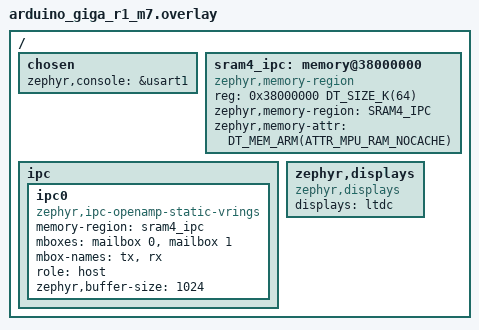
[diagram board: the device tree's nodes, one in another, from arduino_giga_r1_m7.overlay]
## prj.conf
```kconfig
# Gigaspark OS - M7 (Primary Core) Configuration
CONFIG_PRINTK=y
CONFIG_LOG=y
CONFIG_HEAP_MEM_POOL_SIZE=8192
CONFIG_MAIN_STACK_SIZE=4096

# IPC Service
CONFIG_IPC_SERVICE=y
CONFIG_OPENAMP=y
CONFIG_OPENAMP_SLAVE=n

# MBOX driver for STM32 HSEM
CONFIG_MBOX=y

# GPIO for LED
CONFIG_GPIO=y
```

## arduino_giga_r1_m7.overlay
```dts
/*
 * Gigaspark OS - M7 Device Tree Overlay
 * Arduino Giga R1 (STM32H747XI M7)
 *
 * IPC via OpenAMP static vrings over SRAM4
 * LVGL display configuration
 */

#include <zephyr/dt-bindings/ipc_service/static_vrings.h>
#include <zephyr/dt-bindings/memory-attr/memory-attr-arm.h>

/ {
	chosen {
		zephyr,console = &usart1;
	};

	/* SRAM4: 64KB at 0x38000000 (D3 domain, shared between M7 and M4) */
	sram4_ipc: memory@38000000 {
		compatible = "zephyr,memory-region", "mmio-sram";
		reg = <0x38000000 DT_SIZE_K(64)>;
		zephyr,memory-region = "SRAM4_IPC";
		zephyr,memory-attr = <DT_MEM_ARM(ATTR_MPU_RAM_NOCACHE)>;
	};

	/* IPC node for OpenAMP static vrings */
	ipc {
		ipc0: ipc0 {
			compatible = "zephyr,ipc-openamp-static-vrings";
			memory-region = <&sram4_ipc>;
			mboxes = <&mailbox 0>, <&mailbox 1>;
			mbox-names = "tx", "rx";
			role = "host";
			zephyr,buffer-size = <1024>;
			status = "okay";
		};
	};

	/* LVGL display configuration - references the LTDC */
	zephyr,displays {
		compatible = "zephyr,displays";
		displays = <&ltdc>;
	};
};
```

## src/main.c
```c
/*
 * Gigaspark OS - M7 Primary Core
 * STM32H747XI Cortex-M7 @ 480MHz
 *
 * Architecture: 2 Dedicated Threads (Strict Multiplexation)
 *
 * Thread 1 - ui_launcher (Priority: Low):
 *   EXCLUSIVELY handles LVGL rendering, touch input, and the app menu.
 *   Runs lv_timer_handler() in a tight loop at 5ms intervals.
 *   Manages the navigation bar (Home button).
 *
 * Thread 2 - app_runner (Priority: High):
 *   EXCLUSIVELY executes user apps (app_main()) and handles the SDK.
 *   Communicates with M4 via IPC for memory and filesystem ops.
 *   Can be aborted by ui_launcher when Home is pressed.
 *
 * Communication: main() initializes everything, then threads take over.
 */

#include <zephyr/kernel.h>
#include <zephyr/device.h>
#include <zephyr/drivers/gpio.h>
#include <zephyr/ipc/ipc_service.h>
#include <zephyr/logging/log.h>

#include "ipc_config.h"
#include "ipc_protocol.h"
#include "fault_manager.h"
#include "app_runner.h"
#include "nav_bar.h"
#include "power_manager.h"
#include "net_manager.h"
#include "app_downloader.h"

LOG_MODULE_REGISTER(gigaspark_m7, CONFIG_LOG_DEFAULT_LEVEL);

/* SDK init */
extern void gigaspark_sdk_init(void);

/* Green LED = PJ13 (alias led1) */
static const struct gpio_dt_spec led_green = GPIO_DT_SPEC_GET(DT_ALIAS(led1), gpios);

/* ============================================================
 * IPC Layer (shared by both threads)
 * ============================================================ */

static struct ipc_ept ept;
static volatile bool ept_ready;
static K_SEM_DEFINE(bound_sem, 0, 1);
static K_SEM_DEFINE(data_sem, 0, 1);

/* Last response from M4 */
static struct ipc_msg last_resp;

/* Shared buffer for file writes */
uint8_t g_file_write_buf[FILE_WRITE_CHUNK_MAX];

static void ept_bound(void *priv)
{
	(void)priv;
	ept_ready = true;
	k_sem_give(&bound_sem);
	LOG_INF("Endpoint bound to M4");
}

static void ept_received(const void *data, size_t len, void *priv)
{
	(void)priv;
	if (len < sizeof(struct ipc_msg)) {
		return;
	}

	memcpy(&last_resp, data, sizeof(last_resp));
	k_sem_give(&data_sem);
}

static struct ipc_ept_cfg ept_cfg = {
	.name = IPC_ENDPOINT_NAME,
	.cb = {
		.bound    = ept_bound,
		.received = ept_received,
	},
};

/* Send a command to M4 and wait for response (blocking) */
int send_ipc_cmd(struct ipc_msg *cmd, struct ipc_msg *resp)
{
	int ret;

	ret = ipc_service_send(&ept, cmd, sizeof(*cmd));
	if (ret < 0) {
		LOG_ERR("Send failed: %d", ret);
		return ret;
	}

	k_sem_take(&data_sem, K_FOREVER);
	memcpy(resp, &last_resp, sizeof(*resp));
	return 0;
}

/* ============================================================
 * UI Launcher Thread (Low Priority)
 * EXCLUSIVELY handles LVGL rendering, touch input, and navigation bar.
 * If an app enters an infinite loop, this thread keeps running.
 * ============================================================ */

static void ui_launcher_thread(void *p1, void *p2, void *p3)
{
	(void)p1; (void)p2; (void)p3;
	LOG_INF("UI Launcher thread starting...");

	/* Initialize navigation bar */
	nav_bar_init();

	/* Initialize power manager */
	power_manager_init();

	/*
	 * TODO: When LVGL display driver is ready, this thread will:
	 *   while (1) {
	 *       lv_timer_handler();  // Processes touch, renders UI
	 *       k_msleep(5);         // 5ms = 200 FPS max
	 *   }
	 *
	 * For now, it runs a simple LED blink to show it's alive.
	 */

	while (1) {
		/* Blink LED to show UI thread is running */
		gpio_pin_toggle_dt(&led_green);
		k_msleep(500);
	}
}

/* Static thread: UI launcher, low priority (PRIORITY=14) */
K_THREAD_DEFINE(ui_launcher_tid, 4096,
		ui_launcher_thread, NULL, NULL, NULL,
		14, 0, 0);

/* ============================================================
 * App Runner Thread (High Priority)
 * EXCLUSIVELY executes user apps and handles SDK operations.
 * Communicates with M4 via IPC.
 * ============================================================ */

static void app_runner_thread(void *p1, void *p2, void *p3)
{
	(void)p1; (void)p2; (void)p3;
	int ret;

	LOG_INF("App Runner thread starting...");

	/* Set up thread reference for force exit */
	app_runner_set_thread(k_current_get());

	/* Wait for IPC to be ready */
	k_sem_take(&bound_sem, K_FOREVER);

	/* === WiFi Connection (stub) === */
	LOG_INF("=== Connecting to WiFi ===");
	ret = net_connect_wifi("Gigaspark-AP", "gigaspark123");
	if (ret < 0) {
		LOG_WRN("WiFi connection failed: %d", ret);
	} else {
		ret = net_wait_ip(10000);
		if (ret < 0) {
			LOG_WRN("Failed to get IP: %d", ret);
		} else {
			char ip[16];
			net_get_ip_str(ip, sizeof(ip));
			LOG_INF("Connected! IP: %s", ip);

			/* Try to download an app */
			LOG_INF("=== Downloading app from server ===");
			ret = download_app_from_url(
				"192.168.1.100", 80,
				"/apps/clicker.bin", "clicker.bin"
			);
			if (ret < 0) {
				LOG_WRN("Download failed: %d", ret);
			} else {
				LOG_INF("App downloaded successfully!");
			}
		}
	}

	/* === App Manager === */
	LOG_INF("=== Gigaspark OS App Manager ===");

	/* Get app list from M4 */
	struct ipc_msg list_cmd = {
		.cmd = CMD_GET_APP_LIST,
		.handle = 0,
		.size = 0,
		.status = 0,
	};
	struct ipc_msg resp;

	ret = send_ipc_cmd(&list_cmd, &resp);
	if (ret < 0) {
		LOG_ERR("Failed to get app list: %d", ret);
	} else if (resp.status == STATUS_OK) {
		int app_count = resp.size;
		LOG_INF("Found %d app(s) on SD card", app_count);

		/* Load and execute first app if available */
		if (app_count > 0) {
			LOG_INF("--- Loading app 0 ---");

			struct ipc_msg load_cmd = {
				.cmd = CMD_LOAD_APP,
				.handle = 0,
				.size = 0,
				.status = 0,
			};

			ret = send_ipc_cmd(&load_cmd, &resp);
			if (ret == 0 && resp.status == STATUS_OK) {
				LOG_INF("App loaded: handle=0x%04x, size=%u bytes",
					resp.handle, resp.size);

				/* Show navigation bar */
				nav_bar_show();

				/* Execute app with fault recovery */
				LOG_INF("Executing app with fault recovery...");
				int app_result = app_runner_execute(
					(const uint8_t *)(uintptr_t)resp.handle,
					resp.size,
					resp.handle
				);

				/* Hide navigation bar when app exits */
				nav_bar_hide();

				if (app_result == APP_RESULT_FAULT) {
					LOG_WRN("App faulted - recovered, returning to launcher");
				} else if (app_result == APP_RESULT_OK) {
					LOG_INF("App exited normally");
				} else {
					LOG_ERR("App execution error: %d", app_result);
				}
			}
		}
	}

	LOG_INF("App Runner: entering idle loop");

	/* App runner thread idle - waits for next app to execute */
	while (1) {
		k_msleep(1000);
	}
}

/* Static thread: App runner, high priority (PRIORITY=5) */
K_THREAD_DEFINE(app_runner_tid, 8192,
		app_runner_thread, NULL, NULL, NULL,
		5, 0, 0);

/* ============================================================
 * Main (Initialization Only)
 * Initializes hardware and subsystems, then threads take over.
 * ============================================================ */

int main(void)
{
	int ret;

	LOG_INF("====================================================");
	LOG_INF(" GIGASPARK OS v0.2.0");
	LOG_INF(" M7 @ 480MHz | M4 @ 240MHz");
	LOG_INF(" Architecture: 2 cores x 2 threads = 4 threads");
	LOG_INF("====================================================");
	LOG_INF("M7 Primary Core starting...");

	/* Initialize GPIO for green LED */
	if (!gpio_is_ready_dt(&led_green)) {
		LOG_ERR("GPIO device not ready");
		return -ENODEV;
	}

	ret = gpio_pin_configure_dt(&led_green, GPIO_OUTPUT_INACTIVE);
	if (ret < 0) {
		LOG_ERR("Failed to configure LED: %d", ret);
		return ret;
	}

	/* Initialize fault manager */
	fault_manager_init();
	LOG_INF("Fault manager: OK");

	/* Initialize SDK */
	gigaspark_sdk_init();
	LOG_INF("SDK export table: OK");

	/* Initialize network */
	ret = net_manager_init();
	if (ret < 0) {
		LOG_WRN("Network init failed: %d", ret);
	} else {
		LOG_INF("Network manager: OK");
	}

	/* Initialize IPC */
	const struct device *ipc_instance = DEVICE_DT_GET(DT_NODELABEL(ipc0));

	ret = ipc_service_open_instance(ipc_instance);
	if (ret < 0 && ret != -EALREADY) {
		LOG_ERR("Failed to open IPC instance: %d", ret);
		return ret;
	}

	ret = ipc_service_register_endpoint(ipc_instance, &ept, &ept_cfg);
	if (ret < 0) {
		LOG_ERR("Failed to register endpoint: %d", ret);
		return ret;
	}

	LOG_INF("IPC endpoint: OK");
	LOG_INF("====================================================");
	LOG_INF(" M7 Threads:");
	LOG_INF("   ui_launcher: tid=%d, prio=14 (LOW)", (int)ui_launcher_tid);
	LOG_INF("   app_runner:  tid=%d, prio=5 (HIGH)", (int)app_runner_tid);
	LOG_INF("====================================================");

	/* main() thread sleeps forever - threads do all the work */
	return 0;
}
```

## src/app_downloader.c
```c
/*
 * Gigaspark OS - App Downloader Implementation
 * HTTP client stub for downloading apps
 *
 * Note: Full HTTP support requires network stack.
 * This provides a stub implementation for future development.
 */

#include "app_downloader.h"
#include "ipc_config.h"
#include "ipc_protocol.h"

#include <zephyr/kernel.h>
#include <zephyr/logging/log.h>
#include <string.h>
#include <stdio.h>

LOG_MODULE_REGISTER(app_downloader, CONFIG_LOG_DEFAULT_LEVEL);

/* Shared buffer for file writes */
extern uint8_t g_file_write_buf[FILE_WRITE_CHUNK_MAX];

/* Send a command to M4 and wait for response */
extern int send_ipc_cmd(struct ipc_msg *cmd, struct ipc_msg *resp);

int download_app_from_url(const char *host, uint16_t port,
			  const char *url, const char *app_name)
{
	(void)host;
	(void)port;
	(void)url;
	(void)app_name;

	LOG_WRN("App download not available (network not ready)");
	LOG_INF("Would download from: http://%s:%d%s", host ? host : "", port, url ? url : "");
	LOG_INF("Would save as: %s", app_name ? app_name : "");
	return -ENOTSUP;
}

int download_app_from_url_string(const char *full_url, const char *app_name)
{
	(void)full_url;
	(void)app_name;

	LOG_WRN("App download not available (network not ready)");
	LOG_INF("Would download from: %s", full_url ? full_url : "");
	LOG_INF("Would save as: %s", app_name ? app_name : "");
	return -ENOTSUP;
}
```

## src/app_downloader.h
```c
/*
 * Gigaspark OS - App Downloader Header
 * HTTP client for downloading apps from a local server
 */

#ifndef GIGASPARK_APP_DOWNLOADER_H
#define GIGASPARK_APP_DOWNLOADER_H

#include <stdint.h>
#include <stddef.h>

/* Download result codes */
#define DOWNLOAD_OK             0
#define DOWNLOAD_ERR_SOCKET    (-1)
#define DOWNLOAD_ERR_CONNECT   (-2)
#define DOWNLOAD_ERR_HTTP      (-3)
#define DOWNLOAD_ERR_TIMEOUT   (-4)
#define DOWNLOAD_ERR_IO        (-5)
#define DOWNLOAD_ERR_NO_SD     (-6)
#define DOWNLOAD_ERR_M4        (-7)

/*
 * Download an app from a remote HTTP server and save it to SD card.
 *
 * The app is downloaded in chunks and sent to M4 via IPC
 * for writing to /SD:/apps/<app_name>.bin.
 *
 * @param host       Hostname or IP of the HTTP server.
 * @param port       TCP port (typically 80).
 * @param url        URL path to the .bin file (e.g., "/apps/clicker.bin").
 * @param app_name   Name to save as on SD (e.g., "clicker.bin").
 * @return           DOWNLOAD_OK on success, negative error code.
 */
int download_app_from_url(const char *host, uint16_t port,
			  const char *url, const char *app_name);

/*
 * Download an app using a full URL string.
 *
 * Parses "http://host:port/path" format.
 *
 * @param full_url   Full URL string.
 * @param app_name   Name to save as on SD.
 * @return           DOWNLOAD_OK on success, negative error code.
 */
int download_app_from_url_string(const char *full_url, const char *app_name);

#endif /* GIGASPARK_APP_DOWNLOADER_H */
```

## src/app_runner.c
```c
/*
 * Gigaspark OS - App Runner Implementation
 * Dynamic app execution with HardFault recovery and safe termination
 *
 * Uses setjmp/longjmp for try-catch style fault recovery.
 * The fault handler triggers PendSV, which calls longjmp()
 * from thread mode (safe on Cortex-M).
 *
 * app_force_exit() provides clean termination when the user
 * presses the Home button in the navigation bar.
 */

#include "app_runner.h"
#include "fault_manager.h"
#include "ipc_protocol.h"

#include <zephyr/kernel.h>
#include <zephyr/cache.h>
#include <zephyr/logging/log.h>
#include <setjmp.h>
#include <string.h>

LOG_MODULE_REGISTER(app_runner, CONFIG_LOG_DEFAULT_LEVEL);

/* App memory region base address (after kernel, in SRAM) */
#define APP_MEMORY_BASE  0x24000000  /* DTCM or SRAM1 */
#define APP_MEMORY_SIZE  (128 * 1024) /* 128KB for apps */

/* App function pointer type */
typedef void (*app_main_fn)(void);

/* Current app state */
static bool app_running = false;
static uint16_t current_handle = 0;

/* App thread reference (set by app_runner_thread in main.c) */
static k_tid_t app_thread_id = NULL;

void app_runner_set_thread(k_tid_t tid)
{
	app_thread_id = tid;
}

bool app_runner_is_running(void)
{
	return app_running;
}

int app_runner_setup_mpu(uint32_t app_base, size_t app_size)
{
	LOG_INF("MPU: App region at 0x%08x, size %u bytes", app_base, app_size);
	return 0;
}

void app_runner_disable_mpu(void)
{
	LOG_INF("MPU: App execution region disabled");
}

/*
 * Force exit the currently running app.
 * Called by the navigation bar when Home is pressed.
 *
 * Execution order (CRITICAL):
 * 1. Disable MPU (stop app code execution)
 * 2. Invalidate L1 data cache (remove stale app data)
 * 3. Invalidate L1 instruction cache (remove stale app code)
 * 4. Abort the app thread (safe termination)
 */
void app_force_exit(void)
{
	if (!app_running) {
		LOG_WRN("No app running to force exit");
		return;
	}

	LOG_INF("=== FORCE EXIT: Cleaning up app ===");

	/* Step 1: Disable MPU first - no more app code execution */
	app_runner_disable_mpu();

	/* Step 2: Invalidate L1 data cache */
	LOG_INF("Force exit: Invalidating L1 data cache...");
	sys_cache_data_invd_all();

	/* Step 3: Invalidate L1 instruction cache */
	LOG_INF("Force exit: Invalidating L1 instruction cache...");
	sys_cache_instr_invd_all();

	/* Step 4: Clear app memory region */
	memset((void *)APP_MEMORY_BASE, 0, APP_MEMORY_SIZE);

	/* Step 5: Abort the app thread */
	if (app_thread_id != NULL) {
		LOG_INF("Force exit: Aborting app thread (tid=%p)", app_thread_id);
		k_thread_abort(app_thread_id);
	}

	/* Step 6: Update state */
	app_running = false;
	fault_manager_app_stop();

	LOG_INF("=== FORCE EXIT: App terminated cleanly ===");
}

int app_runner_execute(const uint8_t *app_data, size_t app_size, uint16_t handle)
{
	struct fault_context *fault_ctx = fault_manager_get_context();
	int result;

	if (app_data == NULL || app_size == 0) {
		LOG_ERR("Invalid app data");
		return APP_RESULT_LOAD_ERR;
	}

	if (app_size > APP_MEMORY_SIZE) {
		LOG_ERR("App too large (%u > %u bytes)", app_size, APP_MEMORY_SIZE);
		return APP_RESULT_MPU_ERR;
	}

	LOG_INF("Preparing app: handle=0x%04x, size=%u bytes", handle, app_size);

	/* Copy app code to execution region */
	uint8_t *exec_base = (uint8_t *)APP_MEMORY_BASE;
	memcpy(exec_base, app_data, app_size);

	/* Setup MPU for app execution */
	int ret = app_runner_setup_mpu(APP_MEMORY_BASE, app_size);
	if (ret < 0) {
		LOG_ERR("MPU setup failed: %d", ret);
		return APP_RESULT_MPU_ERR;
	}

	/* Set up fault recovery */
	current_handle = handle;
	fault_manager_clear_fault();
	fault_manager_app_start();
	app_running = true;

	/* Try-catch: setjmp saves the execution point */
	if (setjmp(fault_ctx->jump_buffer) != 0) {
		/*
		 * We landed here via longjmp from PendSV handler.
		 * A fault occurred during app execution.
		 */
		LOG_ERR("App faulted! Recovering...");

		/* Disable app execution */
		sys_cache_data_invd_all();
		sys_cache_instr_invd_all();
		app_runner_disable_mpu();
		app_running = false;
		fault_manager_app_stop();

		result = APP_RESULT_FAULT;
		goto cleanup;
	}

	/*
	 * Normal execution path.
	 * Cast the app binary to a function pointer and call it.
	 * The app's first function is expected to be app_main().
	 */
	LOG_INF("Launching app at 0x%08x...", APP_MEMORY_BASE);

	app_main_fn app_main = (app_main_fn)(APP_MEMORY_BASE | 1);  /* Thumb mode */
	app_main();

	/* App returned normally */
	LOG_INF("App returned normally");
	result = APP_RESULT_OK;

cleanup:
	/* Clean up */
	sys_cache_data_invd_all();
	sys_cache_instr_invd_all();
	app_runner_disable_mpu();
	app_running = false;
	fault_manager_app_stop();

	return result;
}
```

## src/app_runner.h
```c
/*
 * Gigaspark OS - App Runner Header
 * Dynamic app execution with fault recovery and safe termination
 */

#ifndef GIGASPARK_APP_RUNNER_H
#define GIGASPARK_APP_RUNNER_H

#include <stdint.h>
#include <stddef.h>
#include <stdbool.h>
#include <zephyr/kernel.h>

/* App execution result codes */
#define APP_RESULT_OK           0
#define APP_RESULT_FAULT        (-1)
#define APP_RESULT_LOAD_ERR     (-2)
#define APP_RESULT_MPU_ERR      (-3)
#define APP_RESULT_ABORTED      (-4)

/*
 * Run a user app from a memory buffer.
 */
int app_runner_execute(const uint8_t *app_data, size_t app_size, uint16_t handle);

/*
 * Force exit the currently running app.
 * Called by the navigation bar when Home is pressed.
 * Cleans up cache, disables MPU, aborts the app thread.
 */
void app_force_exit(void);

/*
 * Set up MPU region for app code execution.
 */
int app_runner_setup_mpu(uint32_t app_base, size_t app_size);

/*
 * Disable MPU region for app execution.
 */
void app_runner_disable_mpu(void);

/*
 * Set the thread ID for the app runner thread.
 * Used by app_force_exit() to abort the running app.
 */
void app_runner_set_thread(k_tid_t tid);

/*
 * Check if an app is currently running.
 */
bool app_runner_is_running(void);

#endif /* GIGASPARK_APP_RUNNER_H */
```

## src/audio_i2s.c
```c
/*
 * Gigaspark OS - Motor de Audio I2S Implementation
 * Reproduccion PCM 16-bit estereo via I2S + DMA
 *
 * Usa el driver I2S de Zephyr con DMA para no bloquear la CPU.
 * Los chunks de audio se envian al DAC externo (o integrado)
 * mientras el M7 continua procesando video frames.
 *
 * NOTA: El Arduino Giga R1 no expose I2S por defecto en el DTS.
 * Cuando se habilite el periferico I2S en el overlay, se activara
 * automaticamente el codigo de hardware via CONFIG_I2S.
 */

#include "audio_i2s.h"

#include <zephyr/kernel.h>
#include <zephyr/logging/log.h>
#include <string.h>

LOG_MODULE_REGISTER(audio_i2s, CONFIG_LOG_DEFAULT_LEVEL);

/* Estado del audio */
static volatile bool audio_playing = false;
static volatile bool audio_initialized = false;

#if defined(CONFIG_I2S) && defined(CONFIG_SOC_STM32H747XX)

/* Cuando I2S este habilitado y el SoC lo soporte, usar driver nativo */
#include <zephyr/drivers/i2s.h>

static const struct device *i2s_dev;

#define AUDIO_DMA_BUF_COUNT  4
#define AUDIO_DMA_BUF_SIZE   (AUDIO_BUFFER_FRAMES * AUDIO_CHANNELS * (AUDIO_BITS_PER_SAMPLE / 8))

static int32_t __aligned(32) audio_dma_buf[AUDIO_DMA_BUF_COUNT]
	[AUDIO_BUFFER_FRAMES * AUDIO_CHANNELS];

static int current_buf = 0;

int audio_i2s_init(void)
{
	LOG_INF("Inicializando motor de audio I2S...");

	/* Intentar obtener dispositivo I2S del DTS */
	i2s_dev = DEVICE_DT_GET(DT_NODELABEL(i2s2));

	if (!device_is_ready(i2s_dev)) {
		LOG_WRN("I2S2 no disponible en DTS - modo stub");
		return -ENODEV;
	}

	struct i2s_config i2s_cfg = {
		.word_size = AUDIO_BITS_PER_SAMPLE,
		.channels = AUDIO_CHANNELS,
		.format = I2S_FMT_DATA_FORMAT_I2S,
		.options = I2S_OPT_BIT_CLK_MASTER | I2S_OPT_FRAME_CLK_MASTER,
		.frame_clk_freq = AUDIO_SAMPLE_RATE,
		.mem_slab = NULL,
		.block_size = AUDIO_DMA_BUF_SIZE,
		.timeout = 1000,
	};

	int ret = i2s_configure(i2s_dev, I2S_DIR_TX, &i2s_cfg);
	if (ret < 0) {
		LOG_ERR("I2S configure fallido: %d", ret);
		return ret;
	}

	audio_initialized = true;
	LOG_INF("Motor de audio I2S listo (%d Hz, %d-bit, %d canales)",
		AUDIO_SAMPLE_RATE, AUDIO_BITS_PER_SAMPLE, AUDIO_CHANNELS);
	return 0;
}

int audio_play_chunk(const uint8_t *pcm_data, uint32_t size)
{
	if (!audio_initialized || !pcm_data || size == 0) {
		return -ENODEV;
	}

	uint32_t copy_size = (size > AUDIO_DMA_BUF_SIZE) ? AUDIO_DMA_BUF_SIZE : size;
	memcpy(audio_dma_buf[current_buf], pcm_data, copy_size);

	int ret = i2s_write(i2s_dev, audio_dma_buf[current_buf], copy_size);
	if (ret < 0) {
		LOG_ERR("I2S write fallido: %d", ret);
		return ret;
	}

	current_buf = (current_buf + 1) % AUDIO_DMA_BUF_COUNT;

	if (!audio_playing) {
		audio_playing = true;
		LOG_INF("Audio reproduciendo...");
	}
	return 0;
}

void audio_stop(void)
{
	if (audio_playing) {
		audio_playing = false;
		LOG_INF("Audio detenido");
	}
}

bool audio_is_playing(void) { return audio_playing; }
int audio_get_buffer_level(void) { return audio_playing ? 50 : 0; }

#else /* Stub */

int audio_i2s_init(void)
{
	LOG_WRN("I2S no habilitado - modo stub");
	return -ENODEV;
}

int audio_play_chunk(const uint8_t *pcm_data, uint32_t size)
{
	(void)pcm_data; (void)size;
	return -ENODEV;
}

void audio_stop(void) { }
bool audio_is_playing(void) { return false; }
int audio_get_buffer_level(void) { return 0; }

#endif
```

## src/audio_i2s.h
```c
/*
 * Gigaspark OS - Motor de Audio I2S
 * Reproduccion PCM 16-bit estereo via I2S + DMA
 */

#ifndef GIGASPARK_AUDIO_I2S_H
#define GIGASPARK_AUDIO_I2S_H

#include <stdint.h>
#include <stddef.h>
#include <stdbool.h>

/* Configuracion de audio por defecto */
#define AUDIO_SAMPLE_RATE    44100
#define AUDIO_BITS_PER_SAMPLE 16
#define AUDIO_CHANNELS       2

/* Tamano del buffer de audio (frames) */
#define AUDIO_BUFFER_FRAMES  1024

/*
 * Inicializar el motor de audio I2S.
 *
 * @return  0 en exito, error negativo.
 */
int audio_i2s_init(void);

/*
 * Reproducir un chunk de audio PCM.
 * La operacion es non-blocking (usa DMA interno).
 *
 * @param pcm_data  Datos PCM 16-bit estereo.
 * @param size      Tamano en bytes.
 * @return          0 en exito, error negativo.
 */
int audio_play_chunk(const uint8_t *pcm_data, uint32_t size);

/*
 * Detener reproduccion de audio.
 */
void audio_stop(void);

/*
 * Verificar si el audio esta reproduciendo.
 *
 * @return  true si esta reproduciendo.
 */
bool audio_is_playing(void);

/*
 * Obtener el nivel de buffer (para sync con video).
 *
 * @return  Porcentaje del buffer lleno (0-100).
 */
int audio_get_buffer_level(void);

#endif /* GIGASPARK_AUDIO_I2S_H */
```

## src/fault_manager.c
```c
/*
 * Gigaspark OS - Fault Manager Implementation
 * HardFault recovery for user apps on Cortex-M7
 *
 * Strategy: When a HardFault occurs during app execution, the fault
 * handler sets a flag and uses PendSV to defer recovery to thread mode.
 * The PendSV handler then calls longjmp() to return control to the
 * app_runner, which cleans up and returns to the launcher.
 *
 * This avoids the dangerous pattern of longjmp() from ISR context,
 * which is unsafe on Cortex-M due to exception stacking.
 */

#include "fault_manager.h"

#include <zephyr/kernel.h>
#include <zephyr/logging/log.h>
#include <string.h>

LOG_MODULE_REGISTER(fault_manager, CONFIG_LOG_DEFAULT_LEVEL);

/* Cortex-M7 system registers */
#define SCB_SHCSR    (*(volatile uint32_t *)0xE000ED24)
#define SCB_CFSR     (*(volatile uint32_t *)0xE000ED28)
#define SCB_HFSR     (*(volatile uint32_t *)0xE000ED2C)
#define SCB_MMAR     (*(volatile uint32_t *)0xE000ED34)
#define SCB_BFAR     (*(volatile uint32_t *)0xE000ED38)

/* PendSV priority (lowest possible) */
#define PENDSV_PRIORITY  0xFF
#define SCB_SHPR3        (*(volatile uint32_t *)0xE000ED20)

/* Fault context */
static struct fault_context ctx;

/* PendSV IRQ number on Cortex-M7 */
#define PENDSV_IRQn  (-2)

void fault_manager_init(void)
{
	memset(&ctx, 0, sizeof(ctx));

	/* Set PendSV to lowest priority so it runs after all other ISRs */
	uint32_t priority = SCB_SHPR3;
	priority &= ~(0xFF << 16);  /* Clear PendSV priority bits */
	priority |= (PENDSV_PRIORITY << 16);  /* Set to lowest */
	SCB_SHPR3 = priority;

	LOG_INF("Fault manager initialized");
}

struct fault_context *fault_manager_get_context(void)
{
	return &ctx;
}

bool fault_manager_check_fault(void)
{
	return ctx.fault_occurred;
}

void fault_manager_clear_fault(void)
{
	ctx.fault_occurred = false;
	ctx.fault_pc = 0;
	ctx.fault_lr = 0;
	ctx.fault_cfsr = 0;
}

void fault_manager_app_start(void)
{
	ctx.app_running = true;
	ctx.fault_occurred = false;
}

void fault_manager_app_stop(void)
{
	ctx.app_running = false;
}

/*
 * PendSV handler - called in thread mode after a fault.
 * This is safe to call longjmp() from because we're in thread mode.
 */
void z_arm_pendsv_isr(void *exc_ptr)
{
	(void)exc_ptr;
	if (!ctx.fault_occurred) {
		return;
	}

	LOG_WRN("PendSV: Recovering from fault (PC=0x%08x, CFSR=0x%08x)",
		ctx.fault_pc, ctx.fault_cfsr);

	/* Clear fault state */
	ctx.app_running = false;

	/* longjmp back to app_runner's setjmp point */
	longjmp(ctx.jump_buffer, 1);
}

/*
 * Called from the fault handler stub (see fault_handler_stub.s).
 * This runs in handler mode (ISR context).
 */
void fault_manager_record_fault(uint32_t *stack_frame)
{
	/* Extract stacked registers from the exception frame */
	uint32_t r0  = stack_frame[0];
	uint32_t r1  = stack_frame[1];
	uint32_t r2  = stack_frame[2];
	uint32_t r3  = stack_frame[3];
	uint32_t r12 = stack_frame[4];
	uint32_t lr  = stack_frame[5];
	uint32_t pc  = stack_frame[6];
	uint32_t psr = stack_frame[7];

	(void)r0; (void)r1; (void)r2; (void)r3; (void)r12;
	(void)lr; (void)psr;

	/* Record fault info */
	ctx.fault_pc = pc;
	ctx.fault_lr = lr;
	ctx.fault_cfsr = SCB_CFSR;

	LOG_ERR("=== HardFault Detected ===");
	LOG_ERR("  PC:  0x%08x", pc);
	LOG_ERR("  LR:  0x%08x", lr);
	LOG_ERR("  CFSR: 0x%08x", SCB_CFSR);
	LOG_ERR("  HFSR: 0x%08x", SCB_HFSR);

	/* Decode CFSR bits */
	if (SCB_CFSR & (1 << 0)) LOG_ERR("  IACCVIOL - Instruction access violation");
	if (SCB_CFSR & (1 << 1)) LOG_ERR("  DACCVIOL - Data access violation");
	if (SCB_CFSR & (1 << 3)) LOG_ERR("  MUNSTKERR - MemManage fault on unstacking");
	if (SCB_CFSR & (1 << 4)) LOG_ERR("  MSTKERR - MemManage fault on stacking");
	if (SCB_CFSR & (1 << 7)) LOG_ERR("  MMARVALID - MemManage Address Valid");
	if (SCB_CFSR & (1 << 8)) LOG_ERR("  IBUSERR - Instruction bus error");
	if (SCB_CFSR & (1 << 9)) LOG_ERR("  PRECISERR - Precise data bus error");
	if (SCB_CFSR & (1 << 10)) LOG_ERR("  IMPRECISERR - Imprecise data bus error");
	if (SCB_CFSR & (1 << 11)) LOG_ERR("  UNSTKERR - Bus fault on unstacking");
	if (SCB_CFSR & (1 << 12)) LOG_ERR("  STKERR - Bus fault on stacking");
	if (SCB_CFSR & (1 << 15)) LOG_ERR("  BFARVALID - Bus Fault Address Valid");
	if (SCB_CFSR & (1 << 16)) LOG_ERR("  UNDEFINSTR - Undefined instruction");
	if (SCB_CFSR & (1 << 17)) LOG_ERR("  INVSTATE - Thumb state violation");
	if (SCB_CFSR & (1 << 18)) LOG_ERR("  INVPC - Invalid PC load");
	if (SCB_CFSR & (1 << 19)) LOG_ERR("  NOCP - No coprocessor");
	if (SCB_CFSR & (1 << 24)) LOG_ERR("  DIVBYZERO - Divide by zero");
	if (SCB_CFSR & (1 << 25)) LOG_ERR("  UNALIGNED - Unaligned access");

	LOG_ERR("============================");

	/* Set fault flag */
	ctx.fault_occurred = true;

	/* Trigger PendSV to recover in thread mode */
	/* Set PendSV pending bit */
	volatile uint32_t *icsr = (volatile uint32_t *)0xE000ED04;
	*icsr = (1 << 28);  /* Set PENDSVSET bit */
}
```

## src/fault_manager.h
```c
/*
 * Gigaspark OS - Fault Manager Header
 * HardFault recovery mechanism for user apps
 */

#ifndef GIGASPARK_FAULT_MANAGER_H
#define GIGASPARK_FAULT_MANAGER_H

#include <stdbool.h>
#include <stdint.h>
#include <setjmp.h>

/* Fault recovery context */
struct fault_context {
	jmp_buf  jump_buffer;   /* setjmp/longjmp buffer */
	volatile bool app_running;  /* true while app_main is executing */
	volatile bool fault_occurred; /* set by fault handler */
	volatile uint32_t fault_pc;   /* PC at time of fault */
	volatile uint32_t fault_lr;   /* LR at time of fault */
	volatile uint32_t fault_cfsr; /* Configurable Fault Status Register */
};

/*
 * Initialize the fault manager.
 * Installs the custom HardFault handler.
 */
void fault_manager_init(void);

/*
 * Get the current fault context.
 * Used by app_runner to set up setjmp/longjmp.
 */
struct fault_context *fault_manager_get_context(void);

/*
 * Check if a fault occurred during app execution.
 * Returns true if the app faulted and needs recovery.
 */
bool fault_manager_check_fault(void);

/*
 * Clear the fault state after recovery.
 */
void fault_manager_clear_fault(void);

/*
 * Mark that an app is running (faults should trigger recovery).
 */
void fault_manager_app_start(void);

/*
 * Mark that the app has stopped.
 */
void fault_manager_app_stop(void);

#endif /* GIGASPARK_FAULT_MANAGER_H */
```

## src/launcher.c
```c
/*
 * Gigaspark OS - Launcher Implementation
 * Application launcher menu for LVGL v9 display
 *
 * Requests the app list from M4 via IPC and creates a visual
 * button menu on the 480x272 LTDC display.
 */

#include "launcher.h"
#include "ipc_protocol.h"

#include <zephyr/kernel.h>
#include <zephyr/ipc/ipc_service.h>
#include <zephyr/logging/log.h>
#include <lvgl.h>
#include <string.h>

LOG_MODULE_REGISTER(launcher, CONFIG_LOG_DEFAULT_LEVEL);

/* IPC endpoint reference */
static struct ipc_ept *launcher_ept;

/* App list from M4 */
static struct app_info app_list[APP_MAX_COUNT];
static int app_count = 0;

/* LVGL objects */
static lv_obj_t *main_screen;
static lv_obj_t *status_label;

/* Response synchronization */
static K_SEM_DEFINE(resp_sem, 0, 1);
static struct ipc_msg last_response;

/* Button click event handler */
static void btn_click_cb(lv_event_t *e)
{
	lv_event_code_t code = lv_event_get_code(e);
	lv_obj_t *btn = lv_event_get_target(e);

	if (code != LV_EVENT_CLICKED) {
		return;
	}

	/* Get app id from button user data */
	int btn_id = (int)(intptr_t)lv_event_get_user_data(e);

	if (btn_id < 0 || btn_id >= app_count) {
		LOG_WRN("Invalid button id: %d", btn_id);
		return;
	}

	LOG_INF("App[%d] selected: %s", btn_id, app_list[btn_id].name);

	/* Update status label */
	lv_label_set_text_fmt(status_label, "Loading: %s...", app_list[btn_id].name);

	/* Send CMD_LOAD_APP to M4 */
	struct ipc_msg cmd = {
		.cmd = CMD_LOAD_APP,
		.handle = app_list[btn_id].id,
		.size = 0,
		.status = 0,
	};

	int ret = ipc_service_send(launcher_ept, &cmd, sizeof(cmd));
	if (ret < 0) {
		LOG_ERR("Failed to send CMD_LOAD_APP: %d", ret);
		lv_label_set_text(status_label, "Load failed!");
		return;
	}

	/* Wait for response */
	ret = k_sem_take(&resp_sem, K_MSEC(2000));
	if (ret < 0) {
		LOG_ERR("CMD_LOAD_APP response timeout");
		lv_label_set_text(status_label, "Load timeout!");
		return;
	}

	const struct ipc_msg *resp = (const struct ipc_msg *)&last_response;
	if (resp->status == STATUS_OK) {
		lv_label_set_text_fmt(status_label,
			"Loaded: %s (handle=0x%04x, %u bytes)",
			app_list[btn_id].name, resp->handle, resp->size);
		LOG_INF("App loaded: handle=0x%04x size=%u",
			resp->handle, resp->size);
	} else {
		lv_label_set_text_fmt(status_label,
			"Load error: %d", resp->status);
		LOG_ERR("App load failed: status=%d", resp->status);
	}
}

int launcher_init(struct ipc_ept *ept)
{
	int ret;

	launcher_ept = ept;

	LOG_INF("Launcher: requesting app list from M4...");

	/* Send CMD_GET_APP_LIST to M4 */
	struct ipc_msg cmd = {
		.cmd = CMD_GET_APP_LIST,
		.handle = 0,
		.size = 0,
		.status = 0,
	};

	ret = ipc_service_send(ept, &cmd, sizeof(cmd));
	if (ret < 0) {
		LOG_ERR("Failed to send CMD_GET_APP_LIST: %d", ret);
		return ret;
	}

	/* Wait for response */
	ret = k_sem_take(&resp_sem, K_MSEC(2000));
	if (ret < 0) {
		LOG_ERR("CMD_GET_APP_LIST response timeout");
		return -ETIMEDOUT;
	}

	const struct ipc_msg *resp = (const struct ipc_msg *)&last_response;
	if (resp->status != STATUS_OK) {
		LOG_WRN("No apps available (status=%d)", resp->status);
		app_count = 0;
	} else {
		app_count = resp->size;
		LOG_INF("M4 reports %d app(s)", app_count);
	}

	/* Build the LVGL UI */
	main_screen = lv_scr_act();
	lv_obj_set_style_bg_color(main_screen, lv_color_hex(0x1a1a2e), 0);

	/* Title */
	lv_obj_t *title = lv_label_create(main_screen);
	lv_label_set_text(title, "Gigaspark OS - Launcher");
	lv_obj_set_style_text_font(title, &lv_font_montserrat_14, 0);
	lv_obj_set_style_text_color(title, lv_color_hex(0xe94560), 0);
	lv_obj_align(title, LV_ALIGN_TOP_MID, 0, 10);

	/* Create buttons for each app */
	if (app_count > 0) {
		for (int i = 0; i < app_count && i < APP_MAX_COUNT; i++) {
			lv_obj_t *btn = lv_btn_create(main_screen);
			lv_obj_set_size(btn, 420, 36);
			lv_obj_align(btn, LV_ALIGN_TOP_MID, 0, 50 + i * 42);

			/* Button style */
			lv_obj_set_style_bg_color(btn, lv_color_hex(0x16213e), 0);
			lv_obj_set_style_border_color(btn, lv_color_hex(0x0f3460), 0);
			lv_obj_set_style_border_width(btn, 2, 0);
			lv_obj_set_style_radius(btn, 8, 0);

			/* Button label */
			lv_obj_t *label = lv_label_create(btn);
			lv_label_set_text(label, app_list[i].name);
			lv_obj_set_style_text_color(label, lv_color_hex(0xffffff), 0);
			lv_obj_center(label);

			/* Click event */
			lv_obj_add_event_cb(btn, btn_click_cb, LV_EVENT_CLICKED,
					    (void *)(intptr_t)i);
		}
	} else {
		lv_obj_t *no_apps = lv_label_create(main_screen);
		lv_label_set_text(no_apps,
			"No apps found on SD card.\n"
			"Insert SD with /apps/*.bin files.");
		lv_obj_set_style_text_color(no_apps, lv_color_hex(0xaaaaaa), 0);
		lv_obj_align(no_apps, LV_ALIGN_CENTER, 0, 0);
	}

	/* Status label at bottom */
	status_label = lv_label_create(main_screen);
	lv_label_set_text(status_label, "Ready");
	lv_obj_set_style_text_color(status_label, lv_color_hex(0x53d769), 0);
	lv_obj_align(status_label, LV_ALIGN_BOTTOM_MID, 0, -10);

	LOG_INF("Launcher UI created");
	return 0;
}

void launcher_handle_response(const void *resp_data)
{
	if (resp_data == NULL) {
		return;
	}

	memcpy(&last_response, resp_data, sizeof(last_response));
	k_sem_give(&resp_sem);
}
```

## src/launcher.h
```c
/*
 * Gigaspark OS - Launcher Header
 * Application launcher menu for LVGL display
 */

#ifndef GIGASPARK_LAUNCHER_H
#define GIGASPARK_LAUNCHER_H

#include <zephyr/ipc/ipc_service.h>

/*
 * Initialize the launcher.
 * Requests the app list from M4 via IPC and creates a button
 * menu on the LVGL display.
 *
 * @param ept  IPC endpoint for communication with M4.
 * @return     0 on success, negative error code on failure.
 */
int launcher_init(struct ipc_ept *ept);

/*
 * Handle an IPC response from M4.
 * Called by the main IPC received callback when a response arrives.
 *
 * @param resp  Pointer to the received IPC message.
 */
void launcher_handle_response(const void *resp);

#endif /* GIGASPARK_LAUNCHER_H */
```

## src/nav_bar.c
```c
/*
 * Gigaspark OS - Navigation Bar Implementation
 * Android-style OS overlay with Home button
 *
 * The navigation bar is drawn by the OS (not the app) and sits
 * on top of everything. When the user taps the Home button,
 * the OS aborts the running app and returns to the launcher.
 *
 * Note: LVGL is stubbed out until display driver is ready.
 * The logic and flow are complete.
 */

#include "nav_bar.h"
#include "app_runner.h"

#include <zephyr/kernel.h>
#include <zephyr/logging/log.h>

LOG_MODULE_REGISTER(nav_bar, CONFIG_LOG_DEFAULT_LEVEL);

/* Navigation bar state */
static bool nav_bar_initialized = false;
static bool nav_bar_visible = false;
static bool home_btn_pressed = false;

/* Touch zone for nav bar (entire bottom 40px) */
#define TOUCH_ZONE_Y_START  NAV_BAR_Y_START

/*
 * Process Home button press.
 */
static void home_btn_process(void)
{
	if (!home_btn_pressed) {
		return;
	}

	home_btn_pressed = false;

	LOG_INF("HOME BUTTON PRESSED - Aborting app...");

	/* Force exit the running app */
	app_force_exit();

	/* Hide nav bar */
	nav_bar_hide();

	LOG_INF("App terminated, returning to launcher");
}

void nav_bar_init(void)
{
	LOG_INF("Initializing navigation bar...");
	nav_bar_initialized = true;
	nav_bar_visible = false;
	LOG_INF("Navigation bar initialized (stub mode - no LVGL)");
}

void nav_bar_show(void)
{
	if (!nav_bar_initialized) {
		return;
	}

	nav_bar_visible = true;
	LOG_INF("Navigation bar shown");
}

void nav_bar_hide(void)
{
	if (!nav_bar_initialized) {
		return;
	}

	nav_bar_visible = false;
	LOG_INF("Navigation bar hidden");
}

bool nav_bar_touch_hit(int x, int y)
{
	(void)x;
	return nav_bar_visible && (y >= TOUCH_ZONE_Y_START) && (y < SCREEN_HEIGHT);
}

void nav_bar_touch_handler(int x, int y)
{
	if (!nav_bar_visible) {
		return;
	}

	/* Check if touch is in Home button zone (center of nav bar) */
	if (x >= 190 && x <= 290 && y >= NAV_BAR_Y_START + 5 && y <= NAV_BAR_Y_START + 35) {
		home_btn_pressed = true;
		home_btn_process();
	}
}

void *nav_bar_get_obj(void)
{
	return NULL;
}
```

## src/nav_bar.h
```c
/*
 * Gigaspark OS - Navigation Bar Header
 * Android-style OS overlay with Home button
 */

#ifndef GIGASPARK_NAV_BAR_H
#define GIGASPARK_NAV_BAR_H

#include <stdbool.h>

/* Navigation bar dimensions */
#define NAV_BAR_HEIGHT   40
#define NAV_BAR_Y_START  (272 - NAV_BAR_HEIGHT)  /* Bottom of 272px screen */

/* Screen dimensions */
#define SCREEN_WIDTH     480
#define SCREEN_HEIGHT    272

/*
 * Initialize the navigation bar.
 * Must be called after lv_init() and display creation.
 */
void nav_bar_init(void);

/*
 * Show the navigation bar.
 * Called when an app is running.
 */
void nav_bar_show(void);

/*
 * Hide the navigation bar.
 * Called when returning to the launcher.
 */
void nav_bar_hide(void);

/*
 * Check if a touch event is in the navigation bar zone.
 *
 * @param x  Touch X coordinate.
 * @param y  Touch Y coordinate.
 * @return   true if touch is in nav bar area.
 */
bool nav_bar_touch_hit(int x, int y);

/*
 * Handle a touch event in the nav bar zone.
 * Called by the LVGL input callback.
 *
 * @param x  Touch X coordinate.
 * @param y  Touch Y coordinate.
 */
void nav_bar_touch_handler(int x, int y);

/*
 * Get the nav bar object (for LVGL operations).
 */
void *nav_bar_get_obj(void);

#endif /* GIGASPARK_NAV_BAR_H */
```
